VERSION "1.0"

NS_ :

BS_:

BU_: VOICE_ECU CRANE_ECU

BO_ 16 ESTOP: 2 VOICE_ECU
 SG_ Source : 0|8@1+ (1,0) [0|255] "" CRANE_ECU
 SG_ Counter : 8|8@1+ (1,0) [0|255] "" CRANE_ECU

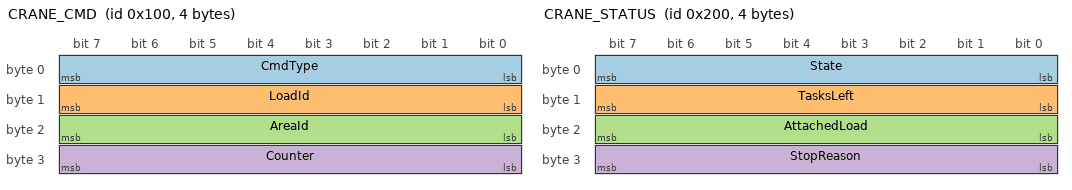
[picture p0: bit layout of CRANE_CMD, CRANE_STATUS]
BO_ 256 CRANE_CMD: 4 VOICE_ECU
 SG_ CmdType : 0|8@1+ (1,0) [0|255] "" CRANE_ECU
 SG_ LoadId : 8|8@1+ (1,0) [0|255] "" CRANE_ECU
 SG_ AreaId : 16|8@1+ (1,0) [0|255] "" CRANE_ECU
 SG_ Counter : 24|8@1+ (1,0) [0|255] "" CRANE_ECU

BO_ 512 CRANE_STATUS: 4 CRANE_ECU
 SG_ State : 0|8@1+ (1,0) [0|255] "" VOICE_ECU
 SG_ TasksLeft : 8|8@1+ (1,0) [0|255] "" VOICE_ECU
 SG_ AttachedLoad : 16|8@1+ (1,0) [0|255] "" VOICE_ECU
 SG_ StopReason : 24|8@1+ (1,0) [0|255] "" VOICE_ECU

BO_ 513 CRANE_ACK: 2 CRANE_ECU
 SG_ Counter : 0|8@1+ (1,0) [0|255] "" VOICE_ECU
 SG_ Result : 8|8@1+ (1,0) [0|255] "" VOICE_ECU

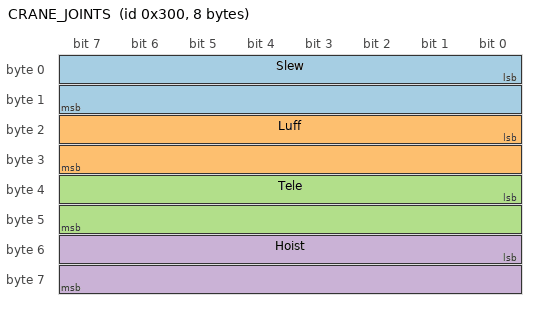
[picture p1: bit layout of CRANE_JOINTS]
BO_ 768 CRANE_JOINTS: 8 CRANE_ECU
 SG_ Slew : 0|16@1- (0.01,0) [-180|180] "deg" VOICE_ECU
 SG_ Luff : 16|16@1- (0.01,0) [0|90] "deg" VOICE_ECU
 SG_ Tele : 32|16@1+ (0.001,0) [0|6] "m" VOICE_ECU
 SG_ Hoist : 48|16@1+ (0.001,0) [0|12] "m" VOICE_ECU

BO_ 1808 VOICE_HEARTBEAT: 1 VOICE_ECU
 SG_ NmtState : 0|8@1+ (1,0) [0|255] "" CRANE_ECU

BO_ 1824 CRANE_HEARTBEAT: 1 CRANE_ECU
 SG_ NmtState : 0|8@1+ (1,0) [0|255] "" VOICE_ECU

CM_ BO_ 16 "Acil durdurma. En kucuk ID = CAN hattinda en yuksek oncelik.";
CM_ BO_ 256 "Sesli kumandadan vince gorev komutu. Counter her yeni komutta artar; ayni Counter tekrar gelirse yok sayilir.";
CM_ BO_ 512 "Vinc durumu, 10 Hz. FAULT: vinc kontrolcusu 2 sn yanit vermedi. StopReason: STOPPED durumunun sebebi.";
CM_ BO_ 513 "Her CRANE_CMD icin sonuc.";
CM_ BO_ 768 "Eklem telemetrisi, 10 Hz.";
CM_ BO_ 1808 "Sesli kumanda heartbeat, 10 Hz. Vinc calisirken 1 sn gelmezse vinc durur (dead-man).";
CM_ BO_ 1824 "Vinc ECU heartbeat, 1 Hz.";

VAL_ 256 CmdType 1 "MOVE" 2 "PICK" 3 "PLACE" 4 "HOME" ;
VAL_ 256 LoadId 0 "NONE" 1 "kirmizi_kasa" 2 "mavi_kasa" 3 "beyaz_kasa" 4 "beton_blok" ;
VAL_ 256 AreaId 0 "NONE" 1 "stok" 2 "depo" 3 "atolye" 4 "sevkiyat" ;
VAL_ 512 State 0 "IDLE" 1 "BUSY" 2 "STOPPED" 3 "FAULT" ;
VAL_ 512 StopReason 0 "NONE" 1 "OPERATOR" 2 "VISION_MISMATCH" 3 "HEARTBEAT_LOST" ;
VAL_ 512 AttachedLoad 0 "NONE" 1 "kirmizi_kasa" 2 "mavi_kasa" 3 "beyaz_kasa" 4 "beton_blok" ;
VAL_ 513 Result 0 "OK" 1 "BUSY" 2 "UNKNOWN_LOAD" 3 "UNKNOWN_AREA" 4 "AREA_FULL" 5 "UNREACHABLE" 6 "HOOK_OCCUPIED" 7 "HOOK_EMPTY" 8 "BAD_COMMAND" 9 "DUPLICATE" ;
VAL_ 1808 NmtState 5 "OPERATIONAL" ;
VAL_ 1824 NmtState 5 "OPERATIONAL" ;
